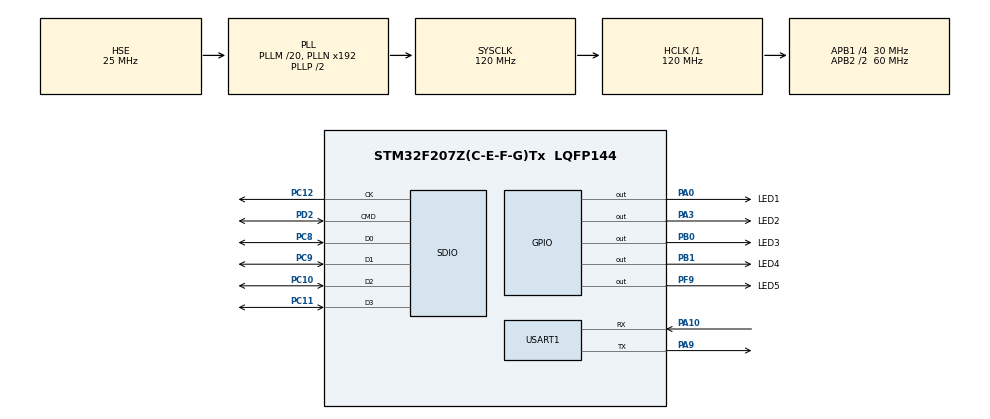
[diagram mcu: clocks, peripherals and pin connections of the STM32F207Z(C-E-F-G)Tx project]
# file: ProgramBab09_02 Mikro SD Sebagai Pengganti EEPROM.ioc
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FATFS._USE_LFN=1
Mcu.Family=STM32F2
Mcu.Name=STM32F207Z(C-E-F-G)Tx
Mcu.Package=LQFP144
NVIC.PriorityGroup=NVIC_PRIORITYGROUP_4
NVIC.USART1_IRQn=true\:0\:0\:false\:false\:true\:true\:true
PA0-WKUP.GPIO_Label=LED1
PA0-WKUP.Signal=GPIO_Output
PA10.Mode=Asynchronous
PA10.Signal=USART1_RX
PA3.GPIO_Label=LED2
PA3.Signal=GPIO_Output
PA9.Mode=Asynchronous
PA9.Signal=USART1_TX
PB0.GPIO_Label=LED3
PB0.Signal=GPIO_Output
PB1.GPIO_Label=LED4
PB1.Signal=GPIO_Output
PC10.Mode=SD_4_bits_Wide_bus
PC10.Signal=SDIO_D2
PC11.Mode=SD_4_bits_Wide_bus
PC11.Signal=SDIO_D3
PC12.Mode=SD_4_bits_Wide_bus
PC12.Signal=SDIO_CK
PC14-OSC32_IN.Mode=LSE-External-Oscillator
PC14-OSC32_IN.Signal=RCC_OSC32_IN
PC15-OSC32_OUT.Mode=LSE-External-Oscillator
PC15-OSC32_OUT.Signal=RCC_OSC32_OUT
PC8.Mode=SD_4_bits_Wide_bus
PC8.Signal=SDIO_D0
PC9.Mode=SD_4_bits_Wide_bus
PC9.Signal=SDIO_D1
PD2.Mode=SD_4_bits_Wide_bus
PD2.Signal=SDIO_CMD
PF9.GPIO_Label=LED5
PF9.Signal=GPIO_Output
PH0-OSC_IN.Mode=HSE-External-Oscillator
PH0-OSC_IN.Signal=RCC_OSC_IN
PH1-OSC_OUT.Mode=HSE-External-Oscillator
PH1-OSC_OUT.Signal=RCC_OSC_OUT
ProjectManager.HeapSize=0x200
ProjectManager.StackSize=0x400
ProjectManager.TargetToolchain=STM32CubeIDE
RCC.48MHZClocksFreq_Value=48000000
RCC.AHBFreq_Value=120000000
RCC.APB1CLKDivider=RCC_HCLK_DIV4
RCC.APB1Freq_Value=30000000
RCC.APB1TimFreq_Value=60000000
RCC.APB2CLKDivider=RCC_HCLK_DIV2
RCC.APB2Freq_Value=60000000
RCC.APB2TimFreq_Value=120000000
RCC.CortexFreq_Value=120000000
RCC.HCLKFreq_Value=120000000
RCC.HSE_VALUE=25000000
RCC.HSI_VALUE=16000000
RCC.PLLM=20
RCC.PLLQ=5
RCC.PLLSourceVirtual=RCC_PLLSOURCE_HSE
RCC.RCC_RTC_Clock_Source=RCC_RTCCLKSOURCE_LSE
RCC.RCC_RTC_Clock_SourceVirtual=RCC_RTCCLKSOURCE_LSE
RCC.SYSCLKFreq_VALUE=120000000
RCC.SYSCLKSource=RCC_SYSCLKSOURCE_PLLCLK
RCC.VCOOutputFreq_Value=240000000
RTC.Format=RTC_FORMAT_BIN
USART1.VirtualMode=VM_ASYNC
VP_FATFS_VS_SDIO.Mode=SDIO
VP_RTC_VS_RTC_Activate.Mode=RTC_Enabled
VP_RTC_VS_RTC_Calendar.Mode=RTC_Calendar
board=custom

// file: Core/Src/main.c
/* USER CODE BEGIN Header */
/**
  ******************************************************************************
  * @file           : main.c
  * @brief          : Main program body
  ******************************************************************************
  * @attention
  *
  * <h2><center>&copy; Copyright (c) 2019 STMicroelectronics.
  * All rights reserved.</center></h2>
  *
  * This software component is licensed by ST under BSD 3-Clause license,
  * the "License"; You may not use this file except in compliance with the
  * License. You may obtain a copy of the License at:
  *                        opensource.org/licenses/BSD-3-Clause
  *
  ******************************************************************************
  */
/* USER CODE END Header */

#include "main.h"
#include "fatfs.h"
#include "rtc.h"
#include "sdio.h"
#include "usart.h"
#include "gpio.h"

/* USER CODE BEGIN Includes */
#include "global.h"
/* USER CODE END Includes */

void SystemClock_Config(void);

int main(void)
{

  /* MCU Configuration--------------------------------------------------------*/

  /* Reset of all peripherals, Initializes the Flash interface and the Systick. */
  HAL_Init();

  /* Configure the system clock */
  SystemClock_Config();

  /* Initialize all configured peripherals */
  MX_GPIO_Init();
  MX_RTC_Init();
  MX_SDIO_SD_Init();
  MX_USART1_UART_Init();
  MX_FATFS_Init();
  /* USER CODE BEGIN 2 */
  printf("Program Mikro SD sebagai pengganti EEPROM\r\n");
  LED_Default();
  //Start DMA Receive for UART
  if(HAL_UART_Receive_IT(&huart1, (uint8_t*)&UartRxBuffer, 1)!=HAL_OK){
	Error_Handler();
  }

  /* USER CODE END 2 */

  /* Infinite loop */
  while (1)
  {

    /* USER CODE BEGIN 3 */
	  LED_Operation();
	  if(pcframe){
		  pc_link();
	  }
  }
  /* USER CODE END 3 */
}

void SystemClock_Config(void)
{
  RCC_OscInitTypeDef RCC_OscInitStruct = {0};
  RCC_ClkInitTypeDef RCC_ClkInitStruct = {0};
  RCC_PeriphCLKInitTypeDef PeriphClkInitStruct = {0};

  /** Initializes the CPU, AHB and APB busses clocks
  */
  RCC_OscInitStruct.OscillatorType = RCC_OSCILLATORTYPE_HSE|RCC_OSCILLATORTYPE_LSE;
  RCC_OscInitStruct.HSEState = RCC_HSE_ON;
  RCC_OscInitStruct.LSEState = RCC_LSE_ON;
  RCC_OscInitStruct.PLL.PLLState = RCC_PLL_ON;
  RCC_OscInitStruct.PLL.PLLSource = RCC_PLLSOURCE_HSE;
  RCC_OscInitStruct.PLL.PLLM = 20;
  RCC_OscInitStruct.PLL.PLLN = 192;
  RCC_OscInitStruct.PLL.PLLP = RCC_PLLP_DIV2;
  RCC_OscInitStruct.PLL.PLLQ = 5;
  if (HAL_RCC_OscConfig(&RCC_OscInitStruct) != HAL_OK)
  {
    Error_Handler();
  }
  /** Initializes the CPU, AHB and APB busses clocks
  */
  RCC_ClkInitStruct.ClockType = RCC_CLOCKTYPE_HCLK|RCC_CLOCKTYPE_SYSCLK
                              |RCC_CLOCKTYPE_PCLK1|RCC_CLOCKTYPE_PCLK2;
  RCC_ClkInitStruct.SYSCLKSource = RCC_SYSCLKSOURCE_PLLCLK;
  RCC_ClkInitStruct.AHBCLKDivider = RCC_SYSCLK_DIV1;
  RCC_ClkInitStruct.APB1CLKDivider = RCC_HCLK_DIV4;
  RCC_ClkInitStruct.APB2CLKDivider = RCC_HCLK_DIV2;

  if (HAL_RCC_ClockConfig(&RCC_ClkInitStruct, FLASH_LATENCY_3) != HAL_OK)
  {
    Error_Handler();
  }
  PeriphClkInitStruct.PeriphClockSelection = RCC_PERIPHCLK_RTC;
  PeriphClkInitStruct.RTCClockSelection = RCC_RTCCLKSOURCE_LSE;
  if (HAL_RCCEx_PeriphCLKConfig(&PeriphClkInitStruct) != HAL_OK)
  {
    Error_Handler();
  }
}

void Error_Handler(void)
{
}

/************************ (C) COPYRIGHT STMicroelectronics *****END OF FILE****/
